# ISP6P5_SYS2 register map
Vendor: Texas Instruments
Peripheral module from a debugger description file (folder TDA2Px).
Registers are 32-bit, read-only, reset 0x1 unless marked. A register's access mark holds for its fields unless they carry their own. Offsets are as the file gives them; lines under a group give offsets from that group; [hi:lo] are bit positions; {n}, {i} and the like mark numbered series; 'fields as' and 'values as' point back to an identical list; <NAME> marks a mode.

## ISP6P5_SYS2
0x00 ISP5_KEY_EN1 — IPIPE eFuse enable.
  [0] KEY1_EN — EFUSE enable Equals 1 when ISP5_EFUSE3_EN = 1 or 0 otherwise.
    0=NEWENUM1 (Disable); 1=NEWENUM2 (Enable)
0x04 ISP5_KEY_EN2 — ISIF eFuse enable.
  [0] KEY1_EN — EFUSE enable Equals 1 when ISP5_EFUSE1_EN = 1 or 0 otherwise.
    0=NEWENUM1 (Disable); 1=NEWENUM2 (Enable)
0x08 ISP5_KEY_EN3 — ISIF eFuse enable.
  [0] KEY_EN — EFUSE enable Equals 1 when ISP5_EFUSE3_EN = 1 or 0 otherwise.
    0=NEWENUM1 (Disable); 1=NEWENUM2 (Enable)
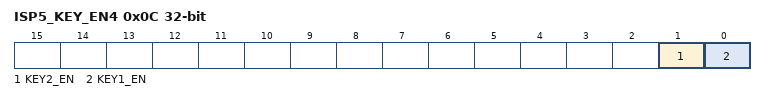
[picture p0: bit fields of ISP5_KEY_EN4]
0x0C ISP5_KEY_EN4 — IPIPEIF eFuse enable.
  [1] KEY2_EN — EFUSE enable Equals 1 when ISP5_EFUSE4_EN = 1 or 0 otherwise.
    0=NEWENUM1 (Disable); 1=NEWENUM2 (Enable)
  [0] KEY1_EN — EFUSE enable Equals 1 when ISP5_EFUSE1_EN = 1 or 0 otherwise.
    0=NEWENUM1 (Disable); 1=NEWENUM2 (Enable)
0x10 ISP5_KEY_EN5 reset 0x0 — H3A eFuse enable.
  [0] KEY_EN — EFUSE enable Equals 1 when ISP5_EFUSE2_EN = 1 or 0 otherwise.
    0=NEWENUM1 (Disable); 1=NEWENUM2 (Enable)
0x14 ISP5_KEY_EN6 — H3A eFuse enable.
  fields as ISP5_KEY_EN3
